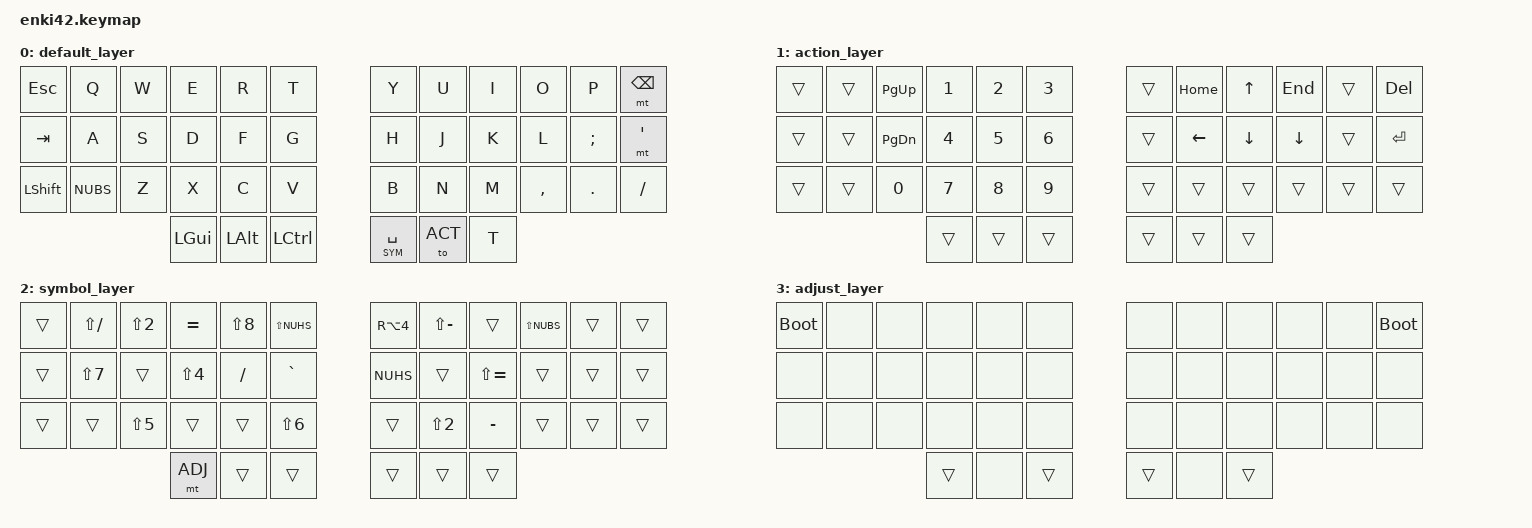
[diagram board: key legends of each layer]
/*
 * Copyright (c) 2020 The ZMK Contributors
 *
 * SPDX-License-Identifier: MIT
 */

#include <behaviors.dtsi>
#include <dt-bindings/zmk/keys.h>
#include <dt-bindings/zmk/bt.h>

#include <dt-bindings/zmk/ext_power.h>

#define DEF 0
#define ACT 1
#define SYM 2
#define ADJ 3

&lt { quick_tap_ms = <220>; };
&mt { quick_tap_ms = <220>; };

/// {
//    behaviors {
//        curly: curly {
//            compatible = "zmk,behavior-tap-dance";
//            #binding-cells = <0>;
//            tapping-term-ms = <200>;
//            bindings = <&kp LS(LBKT)>, <&kp LS(RBKT)>;
//        };
//
//        parenth: parenth {
//            compatible = "zmk,behavior-tap-dance";
//            #binding-cells = <0>;
//            tapping-term-ms = <200>;
//            bindings = <&kp LS(N9)>, <&kp LS(N0)>;
//        };
//
//        sqrbrkt: sqrbrkt {
//            compatible = "zmk,behavior-tap-dance";
//            #binding-cells = <0>;
//            tapping-term-ms = <200>;
//            bindings = <&kp LBKT>, <&kp RBKT>;
//        };
//    };

    keymap {
        compatible = "zmk,keymap";
        
        default_layer {
            bindings = <

  &kp ESC       &kp Q       &kp W   &kp E   &kp R   &kp T                                   &kp Y   &kp U   &kp I   &kp O       &kp P       &mt BKSP 
  &kp TAB       &kp A       &kp S   &kp D   &kp F   &kp G                                   &kp H   &kp J   &kp K   &kp L       &kp SEMI    &mt SQT
  &kp LSHFT     &kp NUBS    &kp Z   &kp X   &kp C   &kp V                                   &kp B   &kp N   &kp M   &kp COMMA   &kp DOT     &kp FSLH
                                        &kp LGUI &kp LALT &kp LCTRL                     &lt SYM SPACE &to ACT &kp T
            >;
        };
        
           
        action_layer {
            bindings = <

&trans  &trans  &kp PG_UP   &kp N1  &kp N2  &kp N3                                  &trans  &kp HOME    &kp UP      &kp END     &trans  &kp DEL
&trans  &trans  &kp PG_DN   &kp N4  &kp N5  &kp N6                                  &trans  &kp LEFT    &kp DOWN    &kp DOWN    &trans  &kp ENTER
&trans  &trans  &kp N0      &kp N7  &kp N8  &kp N9                                  &trans  &trans      &trans      &trans      &trans  &trans
                                    &trans  &trans  &trans                  &trans  &trans  &trans
            >;
        };
        
        symbol_layer {
            bindings = <

&trans  &kp LS(FSLH)    &kp LS(N2)  &kp EQUAL   &kp LS(8)   &kp LS(NUHS)                    &kp RA(N4)  &kp LS(MINUS)   &trans        &kp LS(NUBS)   &trans    &trans
&trans  &kp LS(N7)      &trans      &kp LS(N4)  &kp FSLH    &kp GRAVE                       &kp NUHS    &trans          &kp LS(EQUAL)   &trans      &trans      &trans
&trans  &trans          &kp LS(N5)  &trans      &trans      &kp LS(N6)                      &trans      &kp LS(N2)      &kp MINUS       &trans      &trans      &trans
                                                &mt ADJ      &trans   &trans         &trans  &trans      &trans
            >;     
        };    
        
        adjust_layer {
            bindings = <
&bootloader           &none         &none        &none        &none        &none                             &none        &none        &none        &none        &none         &bootloader
&none     &none    &none        &none        &none        &none                             &none        &none        &none        &none        &none         &none 
&none     &none    &none        &none        &none        &none                             &none        &none        &none        &none        &none         &none 
                                                              &trans       &none     &trans           &trans &none        &trans
            >;
        };
    };
};
